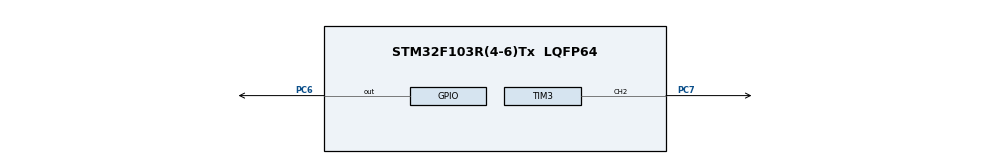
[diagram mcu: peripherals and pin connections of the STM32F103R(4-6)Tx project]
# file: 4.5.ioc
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Mcu.Family=STM32F1
Mcu.Name=STM32F103R(4-6)Tx
Mcu.Package=LQFP64
NVIC.PriorityGroup=NVIC_PRIORITYGROUP_4
PC6.Signal=GPIO_Output
PC7.Signal=S_TIM3_CH2
ProjectManager.HeapSize=0x200
ProjectManager.StackSize=0x400
ProjectManager.TargetToolchain=STM32CubeIDE
RCC.APB1Freq_Value=8000000
RCC.APB2Freq_Value=8000000
SH.S_TIM3_CH2.0=TIM3_CH2,PWM Generation2 CH2
TIM3.Channel-PWM\ Generation2\ CH2=TIM_CHANNEL_2
TIM3.OCMode_PWM-PWM\ Generation2\ CH2=TIM_OCMODE_PWM1
TIM3.OCPolarity_2=TIM_OCPOLARITY_LOW
TIM3.Period=99
TIM3.Prescaler=79
VP_SYS_VS_ND.Mode=No_Debug
VP_TIM3_VS_ClockSourceINT.Mode=Internal
board=custom

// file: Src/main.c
/* USER CODE BEGIN Header */
/**
  ******************************************************************************
  * @file           : main.c
  * @brief          : Main program body
  ******************************************************************************
  * @attention
  *
  * <h2><center>&copy; Copyright (c) 2019 STMicroelectronics.
  * All rights reserved.</center></h2>
  *
  * This software component is licensed by ST under BSD 3-Clause license,
  * the "License"; You may not use this file except in compliance with the
  * License. You may obtain a copy of the License at:
  *                        opensource.org/licenses/BSD-3-Clause
  *
  ******************************************************************************
  */
/* USER CODE END Header */

#include "main.h"

TIM_HandleTypeDef htim3;

void SystemClock_Config(void);
static void MX_GPIO_Init(void);
static void MX_TIM3_Init(void);

int main(void)
{

  /* MCU Configuration--------------------------------------------------------*/

  /* Reset of all peripherals, Initializes the Flash interface and the Systick. */
  HAL_Init();

  /* Configure the system clock */
  SystemClock_Config();

  /* Initialize all configured peripherals */
  MX_GPIO_Init();
  MX_TIM3_Init();
  /* USER CODE BEGIN 2 */
  HAL_TIM_PWM_Start(&htim3,TIM_CHANNEL_2);

  /* USER CODE END 2 */

  /* Infinite loop */
  /* USER CODE BEGIN WHILE */
  while (1)
  {
	  uint8_t i;
	  for(i=0;i<=100;i+=4)
	  {
		  __HAL_TIM_SET_COMPARE(&htim3,TIM_CHANNEL_2,i);
		  HAL_Delay(20);
	  }
	  for(i=100;i>=0;i-=4)
	  {
		  __HAL_TIM_SET_COMPARE(&htim3,TIM_CHANNEL_2,i);
		  HAL_Delay(20);
	  }
    /* USER CODE END WHILE */

  }
}

void SystemClock_Config(void)
{
  RCC_OscInitTypeDef RCC_OscInitStruct = {0};
  RCC_ClkInitTypeDef RCC_ClkInitStruct = {0};

  /** Initializes the CPU, AHB and APB busses clocks
  */
  RCC_OscInitStruct.OscillatorType = RCC_OSCILLATORTYPE_HSI;
  RCC_OscInitStruct.HSIState = RCC_HSI_ON;
  RCC_OscInitStruct.HSICalibrationValue = RCC_HSICALIBRATION_DEFAULT;
  RCC_OscInitStruct.PLL.PLLState = RCC_PLL_NONE;
  if (HAL_RCC_OscConfig(&RCC_OscInitStruct) != HAL_OK)
  {
    Error_Handler();
  }
  /** Initializes the CPU, AHB and APB busses clocks
  */
  RCC_ClkInitStruct.ClockType = RCC_CLOCKTYPE_HCLK|RCC_CLOCKTYPE_SYSCLK
                              |RCC_CLOCKTYPE_PCLK1|RCC_CLOCKTYPE_PCLK2;
  RCC_ClkInitStruct.SYSCLKSource = RCC_SYSCLKSOURCE_HSI;
  RCC_ClkInitStruct.AHBCLKDivider = RCC_SYSCLK_DIV1;
  RCC_ClkInitStruct.APB1CLKDivider = RCC_HCLK_DIV1;
  RCC_ClkInitStruct.APB2CLKDivider = RCC_HCLK_DIV1;

  if (HAL_RCC_ClockConfig(&RCC_ClkInitStruct, FLASH_LATENCY_0) != HAL_OK)
  {
    Error_Handler();
  }
}

static void MX_TIM3_Init(void)
{

  TIM_ClockConfigTypeDef sClockSourceConfig = {0};
  TIM_MasterConfigTypeDef sMasterConfig = {0};
  TIM_OC_InitTypeDef sConfigOC = {0};

  htim3.Instance = TIM3;
  htim3.Init.Prescaler = 79;
  htim3.Init.CounterMode = TIM_COUNTERMODE_UP;
  htim3.Init.Period = 99;
  htim3.Init.ClockDivision = TIM_CLOCKDIVISION_DIV1;
  htim3.Init.AutoReloadPreload = TIM_AUTORELOAD_PRELOAD_DISABLE;
  if (HAL_TIM_Base_Init(&htim3) != HAL_OK)
  {
    Error_Handler();
  }
  sClockSourceConfig.ClockSource = TIM_CLOCKSOURCE_INTERNAL;
  if (HAL_TIM_ConfigClockSource(&htim3, &sClockSourceConfig) != HAL_OK)
  {
    Error_Handler();
  }
  if (HAL_TIM_PWM_Init(&htim3) != HAL_OK)
  {
    Error_Handler();
  }
  sMasterConfig.MasterOutputTrigger = TIM_TRGO_RESET;
  sMasterConfig.MasterSlaveMode = TIM_MASTERSLAVEMODE_DISABLE;
  if (HAL_TIMEx_MasterConfigSynchronization(&htim3, &sMasterConfig) != HAL_OK)
  {
    Error_Handler();
  }
  sConfigOC.OCMode = TIM_OCMODE_PWM1;
  sConfigOC.Pulse = 0;
  sConfigOC.OCPolarity = TIM_OCPOLARITY_LOW;
  sConfigOC.OCFastMode = TIM_OCFAST_DISABLE;
  if (HAL_TIM_PWM_ConfigChannel(&htim3, &sConfigOC, TIM_CHANNEL_2) != HAL_OK)
  {
    Error_Handler();
  }
  HAL_TIM_MspPostInit(&htim3);

}

static void MX_GPIO_Init(void)
{
  GPIO_InitTypeDef GPIO_InitStruct = {0};

  /* GPIO Ports Clock Enable */
  __HAL_RCC_GPIOC_CLK_ENABLE();

  /*Configure GPIO pin Output Level */
  HAL_GPIO_WritePin(GPIOC, GPIO_PIN_6, GPIO_PIN_RESET);

  /*Configure GPIO pin : PC6 */
  GPIO_InitStruct.Pin = GPIO_PIN_6;
  GPIO_InitStruct.Mode = GPIO_MODE_OUTPUT_PP;
  GPIO_InitStruct.Pull = GPIO_NOPULL;
  GPIO_InitStruct.Speed = GPIO_SPEED_FREQ_LOW;
  HAL_GPIO_Init(GPIOC, &GPIO_InitStruct);

}

void Error_Handler(void)
{
}

/************************ (C) COPYRIGHT STMicroelectronics *****END OF FILE****/
